AUTOSAR XML (schema 4-0-3)
package /ComponentTypes
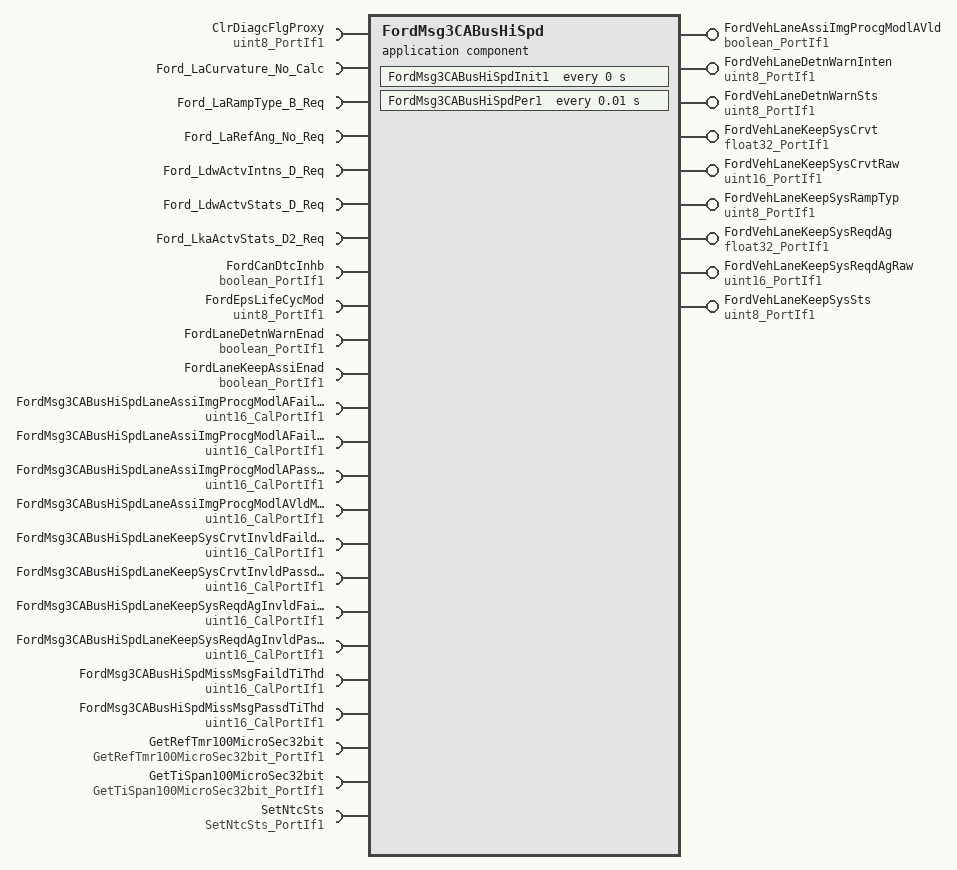
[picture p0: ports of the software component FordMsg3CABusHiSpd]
  application sw component type FordMsg3CABusHiSpd  # The purpose of the Ford Message 3CA Bus Hish Speed function isto provide the Electric Power Steering system with signal values for Lane Detection Warning and Lane Keep Assist functions form CAN.The Ford Message 3CA function will perform the missing message and signal invalid diagnostics as well as provide a validity signal for the signal values and received message
    9 x provide port:
      FordVehLaneAssiImgProcgModlAVld: nonqueued-sender-com-spec{data-element=Logl, init-value=0}, provided-interface=boolean_PortIf1  # This signal Check the validity of Ford Vehicle Turn Signal
      FordVehLaneDetnWarnInten: nonqueued-sender-com-spec{data-element=Val, init-value=0}, provided-interface=uint8_PortIf1  # Vehicle Lane Detection Warning Intensity is assigned to Ford Vehicle LaneDetection Warning Status
      FordVehLaneDetnWarnSts: nonqueued-sender-com-spec{data-element=Val, init-value=0}, provided-interface=uint8_PortIf1  # Vehicle Lane Detection Warning Status is assigned to Ford Vehicle Lane Detection warning Status
      FordVehLaneKeepSysCrvt: nonqueued-sender-com-spec{data-element=Val, init-value=0}, provided-interface=float32_PortIf1  # Processed value of Lane Keep System Curvature to be used by Ford Vehicle System Curvature Quality
      FordVehLaneKeepSysCrvtRaw: nonqueued-sender-com-spec{data-element=Val, init-value=2048}, provided-interface=uint16_PortIf1  # Lane Keep System Curvature is assigned to Ford Vehicle Lane Keep System Curevature Raw
      FordVehLaneKeepSysRampTyp: nonqueued-sender-com-spec{data-element=Val, init-value=0}, provided-interface=uint8_PortIf1  # Lane Keep System Ramp is assigned to Ford Vehicle Lane Keep System Ramp Type
      FordVehLaneKeepSysReqdAg: nonqueued-sender-com-spec{data-element=Val, init-value=0}, provided-interface=float32_PortIf1  # Processed value of Lane Keep System Requested Angle to be used byFord Vehicle System Requested Angle Quality
      FordVehLaneKeepSysReqdAgRaw: nonqueued-sender-com-spec{data-element=Val, init-value=2048}, provided-interface=uint16_PortIf1  # Lane Keep System Requested angle is assigned to Ford Vehicle Lane Keep Requested Angle Raw
      FordVehLaneKeepSysSts: nonqueued-sender-com-spec{data-element=Val, init-value=0}, provided-interface=uint8_PortIf1  # Lane Keep System Status is assigned to Ford Vehicle Lane Keep SystemStatus
    24 x require port:
      ClrDiagcFlgProxy: nonqueued-receiver-com-spec{data-element=Val, filter=data-filter-type=ALWAYS, init-value=0}, required-interface=uint8_PortIf1  # When ClrDiagcFlgProxy is True, Diagnostic test is performed
      Ford_LaCurvature_No_Calc: nonqueued-receiver-com-spec{data-element=Ford_LaCurvature_No_Calc, filter=data-filter-type=ALWAYS, init-value=0}, required-interface=Ford_LaCurvature_No_Calc  # It is a message signal which is received from CAN bus which will be processed
      Ford_LaRampType_B_Req: nonqueued-receiver-com-spec{data-element=Ford_LaRampType_B_Req, filter=data-filter-type=ALWAYS, init-value=0}, required-interface=Ford_LaRampType_B_Req  # It is a message signal which is received from CAN bus which will be processed.Customer datatype should be used. Datatype: Ford_LaRampType_B_Req. Elements are: 0 - "Cx0_Smooth", 1 - "Cx1_Quick
      Ford_LaRefAng_No_Req: nonqueued-receiver-com-spec{data-element=Ford_LaRefAng_No_Req, filter=data-filter-type=ALWAYS, init-value=0}, required-interface=Ford_LaRefAng_No_Req  # It is a message signal which is received from CAN bus which will be processed
      Ford_LdwActvIntns_D_Req: nonqueued-receiver-com-spec{data-element=Ford_LdwActvIntns_D_Req, filter=data-filter-type=ALWAYS, init-value=0}, required-interface=Ford_LdwActvIntns_D_Req  # It is a message signal which is received from CAN bus which will be processed.Customer datatype should be used. Datatype: Ford_LdwActvIntns_D_Req. Elements are: 0 - "Cx0_None", 1 - "Cx1_Low", 2- "Cx2_Medium", 3 - "Cx3_High
      Ford_LdwActvStats_D_Req: nonqueued-receiver-com-spec{data-element=Ford_LdwActvStats_D_Req, filter=data-filter-type=ALWAYS, init-value=0}, required-interface=Ford_LdwActvStats_D_Req  # It is a message signal which is received from CAN bus which will be processed.Customer datatype should be used. Datatype: Ford_LdwActvStats_D_Req. Elements are: 0 - "Cx0_LDW_Idle", 1 - "Cx1_Not_Used1", 2- "Cx2_LDW_Warning_Left", 3 - "Cx3_LDW_Suppress_Left,"4 - "Cx4_LDW_Warning_Right",5 - "Cx5_LDW_Suppress_Right",6 - "Cx6_Not_Used2",7 - "Cx7_LDW_Suppress_Right_Left
      Ford_LkaActvStats_D2_Req: nonqueued-receiver-com-spec{data-element=Ford_LkaActvStats_D2_Req, filter=data-filter-type=ALWAYS, init-value=0}, required-interface=Ford_LkaActvStats_D2_Req  # It is a message signal which is received from CAN bus which will be processed.Customer datatype should be used. Datatype: Ford_LkaActvStats_D2_Req. Elements are: 0 - "Cx0_LkaNoInterv", 1 - "Cx1_LkaIncrIntervLeft", 2- "Cx2_LkaStandIntervLeft", 3 - "Cx3_LkaSupperLeft"4 - "Cx4_LkaStandIntervRight",5 - "Cx5_LkaSupperRight",6 - "Cx6_LkaIncrIntervRight",7 - "Cx7_NotUsed
      FordCanDtcInhb: nonqueued-receiver-com-spec{data-element=Logl, filter=data-filter-type=ALWAYS, init-value=1}, required-interface=boolean_PortIf1  # This signal should be set to false in order to Test Diagnostic NTC,Customer datatype should be used. Data Type: Boolean with Min value "False"(0), Init value "True"(0) and Max value "True"(1)
      FordEpsLifeCycMod: nonqueued-receiver-com-spec{data-element=Val, filter=data-filter-type=ALWAYS, init-value=0}, required-interface=uint8_PortIf1  # This signal is used to decide calibration value to FAIL the NTC
      FordLaneDetnWarnEnad: nonqueued-receiver-com-spec{data-element=Logl, filter=data-filter-type=ALWAYS, init-value=0}, required-interface=boolean_PortIf1  # This signal is set to 1 in order to set the missing NTC to pass or fail.Customer datatype should be used. Data Type: Boolean with Min value "False"(0), Init value "False"(0) and Max value "True"(1)
      FordLaneKeepAssiEnad: nonqueued-receiver-com-spec{data-element=Logl, filter=data-filter-type=ALWAYS, init-value=0}, required-interface=boolean_PortIf1  # This signal is set to 1 in order to set the missing NTC to pass or fail.Customer datatype should be used. Data Type: Boolean with Min value "False"(0), Init value "False"(0) and Max value "True"(1)
      FordMsg3CABusHiSpdLaneAssiImgProcgModlAFaildCrvtTiThd: parameter-require-com-spec{init-value=0, parameter=Val}, required-interface=uint16_CalPortIf1  # Threshold to set Ford Vehicle Lane Assist Image Module A to False
      FordMsg3CABusHiSpdLaneAssiImgProcgModlAFaildReqdAgTiThd: parameter-require-com-spec{init-value=0, parameter=Val}, required-interface=uint16_CalPortIf1  # Threshold to set Ford Vehicle Lane Assist Image Module A to False
      FordMsg3CABusHiSpdLaneAssiImgProcgModlAPassdTiThd: parameter-require-com-spec{init-value=5000, parameter=Val}, required-interface=uint16_CalPortIf1  # Threshold to set Ford Vehicle Lane Assist Image Module A to True
      FordMsg3CABusHiSpdLaneAssiImgProcgModlAVldMissTiThd: parameter-require-com-spec{init-value=1000, parameter=Val}, required-interface=uint16_CalPortIf1  # Threshold to set Ford Vehicle Lane Assist Image Module A Valid to False
      FordMsg3CABusHiSpdLaneKeepSysCrvtInvldFaildTiThd: parameter-require-com-spec{init-value=0, parameter=Val}, required-interface=uint16_CalPortIf1  # Threshold to set invalid message NTC
      FordMsg3CABusHiSpdLaneKeepSysCrvtInvldPassdTiThd: parameter-require-com-spec{init-value=0, parameter=Val}, required-interface=uint16_CalPortIf1  # Threshold to Reset invalid message NTC
      FordMsg3CABusHiSpdLaneKeepSysReqdAgInvldFaildTiThd: parameter-require-com-spec{init-value=0, parameter=Val}, required-interface=uint16_CalPortIf1  # Threshold to set the invalid message NTC
      FordMsg3CABusHiSpdLaneKeepSysReqdAgInvldPassdTiThd: parameter-require-com-spec{init-value=0, parameter=Val}, required-interface=uint16_CalPortIf1  # Threshold to Reset the inavlid message NTC
      FordMsg3CABusHiSpdMissMsgFaildTiThd: parameter-require-com-spec{init-value=1000, parameter=Val}, required-interface=uint16_CalPortIf1  # Threshold to set the missing message NTC
      FordMsg3CABusHiSpdMissMsgPassdTiThd: parameter-require-com-spec{init-value=0, parameter=Val}, required-interface=uint16_CalPortIf1  # Threshold to reset the NTC
      GetRefTmr100MicroSec32bit: client-com-spec=Oper, required-interface=GetRefTmr100MicroSec32bit_PortIf1  # It captures simulation time fromthe SimnTi value obtained at root layer of model and gives the RefTmr
      GetTiSpan100MicroSec32bit: client-com-spec=Oper, required-interface=GetTiSpan100MicroSec32bit_PortIf1  # It Captures simulation time fromSimnTi value, handles counter wrapping, and subtracts RefTmr,provides the TiSpan
      SetNtcSts: client-com-spec=Oper, required-interface=SetNtcSts_PortIf1  # Set the NTC status
    behavior FordMsg3CABusHiSpd_InternalBehavior
      ar-typed-per-instance-memorys:
        22 x data, all with sw-calibration-access=READ-ONLY:
          ClrDiagcFlgProxyPrev: type=uint8  # Clear Diagc Flag Proxy
          FirstTranVldFlg: type=boolean  # This flag is used to indicate the reception of first message
          FordVehLaneAssiImgProcgModlAVldPrev: type=boolean  # Holds previous value of FordVehLaneAssilmgProcgModlAVld when FOrdMsg3CA message is missing
          FordVehLaneDetnWarnIntenPrev: type=uint8  # Holds Previous value of FordVehLaneDetnWarnInten when FordMsg3CA message is missing
          FordVehLaneDetnWarnStsPrev: type=uint8  # Holds Previous value of FordVehLaneDetnWarnSts when FordMsg3Ca message is missing
          FordVehLaneKeepSysCrvtInvldFaildRefTi: type=uint32  # Timer for invalid message will increment or reset based on the conditions
          FordVehLaneKeepSysCrvtInvldPassdRefTi: type=uint32  # Timer for invalid message will increment or reset based on the conditions
          FordVehLaneKeepSysCrvtPrev: type=float32  # Holds previous value of FordVehLaneKeepSysCrvt when FOrdMsg3CA message is missing
          FordVehLaneKeepSysCrvtRawPrev: type=uint16  # Holds previous value of FordVehLaneKeepSysCrvtRaw when FOrdMsg3CA message is missing
          FordVehLaneKeepSysRampTypPrev: type=uint8  # Holds previous value of FordVehLaneKeepSysRamp when FOrdMsg3CA message is missing
          FordVehLaneKeepSysReqdAgInvldPassdRefTi: type=uint32  # Timer for invalid message will increment or reset based on the conditions
          FordVehLaneKeepSysReqdAgPrev: type=float32  # Holds previous value of FordVehLaneKeepSysReqdAg when FOrdMsg3CA message is missing
          FordVehLaneKeepSysReqdAgRawPrev: type=uint16  # Holds previous value of FordVehLaneKeepSysReqdAgRaw when FOrdMsg3CA message is missing
          FordVehLaneKeepSysStsPrev: type=uint8  # Holds previous value of FordVehLaneKeepSysSts when FOrdMsg3CA message is missing
          FordVehMsg3CAMiss: type=boolean  # Flag for missing message diagnostics, it is true when message is missing
          LaneAssiImgProcgModlAFaildCrvtTiThd: type=uint32  # Timer to update Ford Vehicle Lane Assist Image Processing Module A Valid signal as true or false based on calibration
          LaneAssiImgProcgModlAFaildReqdAgTiThd: type=uint32  # Timer to update Ford Vehicle Lane Assist Image Processing Module A Valid signal as true or false based on calibration
          LaneAssiImgProcgModlAVldMissRefTi: type=uint32  # Timer for valid message will increment or reset based on the conditions
          LaneAssiImgProcgModlAVldPassdRefTi: type=uint32  # Timer for valid message will increment or reset based on the conditions
          LaneKeepSysReqdAgInvldFaildRefTi: type=uint32  # Timer for invalid message will increment or reset based on the conditions
          MissMsgFaildRefTi: type=uint32  # Timer for missing message will increment or reset based on the conditions
          MissMsgPassdRefTi: type=uint32  # Timer for missing message will increment or reset based on the conditions
      timing event FordMsg3CABusHiSpd_InitEvent: start-on-event=FordMsg3CABusHiSpdInit1, period=0
      timing event TMT_FordMsg3CABusHiSpdPer1: start-on-event=FordMsg3CABusHiSpdPer1, period=0.01
      port-api-options:
        enable-take-address=false, indirect-api=false, port=Ford_LaCurvature_No_Calc
        enable-take-address=false, indirect-api=false, port=Ford_LaRampType_B_Req
        enable-take-address=false, indirect-api=false, port=Ford_LdwActvIntns_D_Req
        enable-take-address=false, indirect-api=false, port=Ford_LdwActvStats_D_Req
        enable-take-address=false, indirect-api=false, port=FordCanDtcInhb
        enable-take-address=false, indirect-api=false, port=FordMsg3CABusHiSpdLaneAssiImgProcgModlAVldMissTiThd
        enable-take-address=false, indirect-api=false, port=FordMsg3CABusHiSpdLaneKeepSysCrvtInvldFaildTiThd
        enable-take-address=false, indirect-api=false, port=FordMsg3CABusHiSpdLaneKeepSysReqdAgInvldFaildTiThd
        enable-take-address=false, indirect-api=false, port=FordMsg3CABusHiSpdLaneKeepSysReqdAgInvldPassdTiThd
        enable-take-address=false, indirect-api=false, port=FordMsg3CABusHiSpdMissMsgPassdTiThd
        enable-take-address=false, indirect-api=false, port=FordVehLaneAssiImgProcgModlAVld
        enable-take-address=false, indirect-api=false, port=FordVehLaneDetnWarnInten
        enable-take-address=false, indirect-api=false, port=FordVehLaneDetnWarnSts
        enable-take-address=false, indirect-api=false, port=FordVehLaneKeepSysCrvt
        enable-take-address=false, indirect-api=false, port=FordVehLaneKeepSysRampTyp
        enable-take-address=false, indirect-api=false, port=FordVehLaneKeepSysReqdAg
        enable-take-address=false, indirect-api=false, port=FordVehLaneKeepSysReqdAgRaw
        enable-take-address=false, indirect-api=false, port=GetRefTmr100MicroSec32bit
        enable-take-address=false, indirect-api=false, port=GetTiSpan100MicroSec32bit
      runnable FordMsg3CABusHiSpdInit1  # Initialization Runnable
        sync call SC_GetRefTmr100MicroSec32bit_Oper: operation=GetRefTmr100MicroSec32bit.Oper, timeout=0
      runnable FordMsg3CABusHiSpdPer1: minimum-start-interval=0.01  # Periodic Runnable at 10 milli-seconds
        data-receive-point-by-arguments:
          11 x access:
            REC_ClrDiagcFlgProxy_Val: accessed-variable=ClrDiagcFlgProxy.Val
            REC_Ford_LaCurvature_No_Calc_Ford_LaCurvature_No_Calc: accessed-variable=Ford_LaCurvature_No_Calc.Ford_LaCurvature_No_Calc
            REC_Ford_LaRampType_B_Req_Ford_LaRampType_B_Req: accessed-variable=Ford_LaRampType_B_Req.Ford_LaRampType_B_Req
            REC_Ford_LaRefAng_No_Req_Ford_LaRefAng_No_Req: accessed-variable=Ford_LaRefAng_No_Req.Ford_LaRefAng_No_Req
            REC_Ford_LdwActvIntns_D_Req_Ford_LdwActvIntns_D_Req: accessed-variable=Ford_LdwActvIntns_D_Req.Ford_LdwActvIntns_D_Req
            REC_Ford_LdwActvStats_D_Req_Ford_LdwActvStats_D_Req: accessed-variable=Ford_LdwActvStats_D_Req.Ford_LdwActvStats_D_Req
            REC_Ford_LkaActvStats_D2_Req_Ford_LkaActvStats_D2_Req: accessed-variable=Ford_LkaActvStats_D2_Req.Ford_LkaActvStats_D2_Req
            REC_FordCanDtcInhb_Logl: accessed-variable=FordCanDtcInhb.Logl
            REC_FordEpsLifeCycMod_Val: accessed-variable=FordEpsLifeCycMod.Val
            REC_FordLaneDetnWarnEnad_Logl: accessed-variable=FordLaneDetnWarnEnad.Logl
            REC_FordLaneKeepAssiEnad_Logl: accessed-variable=FordLaneKeepAssiEnad.Logl
        data-send-points:
          9 x access:
            SEND_FordVehLaneAssiImgProcgModlAVld_Logl: accessed-variable=FordVehLaneAssiImgProcgModlAVld.Logl
            SEND_FordVehLaneDetnWarnInten_Val: accessed-variable=FordVehLaneDetnWarnInten.Val
            SEND_FordVehLaneDetnWarnSts_Val: accessed-variable=FordVehLaneDetnWarnSts.Val
            SEND_FordVehLaneKeepSysCrvt_Val: accessed-variable=FordVehLaneKeepSysCrvt.Val
            SEND_FordVehLaneKeepSysCrvtRaw_Val: accessed-variable=FordVehLaneKeepSysCrvtRaw.Val
            SEND_FordVehLaneKeepSysRampTyp_Val: accessed-variable=FordVehLaneKeepSysRampTyp.Val
            SEND_FordVehLaneKeepSysReqdAg_Val: accessed-variable=FordVehLaneKeepSysReqdAg.Val
            SEND_FordVehLaneKeepSysReqdAgRaw_Val: accessed-variable=FordVehLaneKeepSysReqdAgRaw.Val
            SEND_FordVehLaneKeepSysSts_Val: accessed-variable=FordVehLaneKeepSysSts.Val
        sync call SC_GetRefTmr100MicroSec32bit_Oper: operation=GetRefTmr100MicroSec32bit.Oper, timeout=0
        sync call SC_GetTiSpan100MicroSec32bit_Oper: operation=GetTiSpan100MicroSec32bit.Oper, timeout=0
        sync call SC_SetNtcSts_Oper: operation=SetNtcSts.Oper, timeout=0
  swc implementation FordMsg3CABusHiSpd_Implementation: behavior=FordMsg3CABusHiSpd_InternalBehavior
    code-descriptors:
      code Default: artifact-descriptors=autosar-engineering-object={short-label=Default, category=SWSRC}
